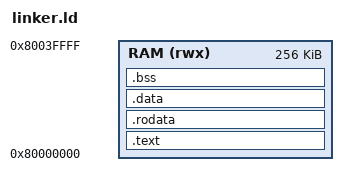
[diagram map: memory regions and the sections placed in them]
ENTRY(_start)

MEMORY
{
    RAM (rwx) : ORIGIN = 0x80000000, LENGTH = 256K
}

SECTIONS {
    .text : {
        *(.text.init)
        *(.text*)
    } > RAM

    .rodata : {
        *(.rodata*)
    } > RAM

    .data : {
        *(.data*)
    } > RAM

    .bss : {
        _bss_start = .;
        *(.bss*)
        *(COMMON)
        _bss_end = .;
    } > RAM

    . = ALIGN(16);
    _stack_top = ORIGIN(RAM) + LENGTH(RAM); /* Stack at top of 256KB */
}
